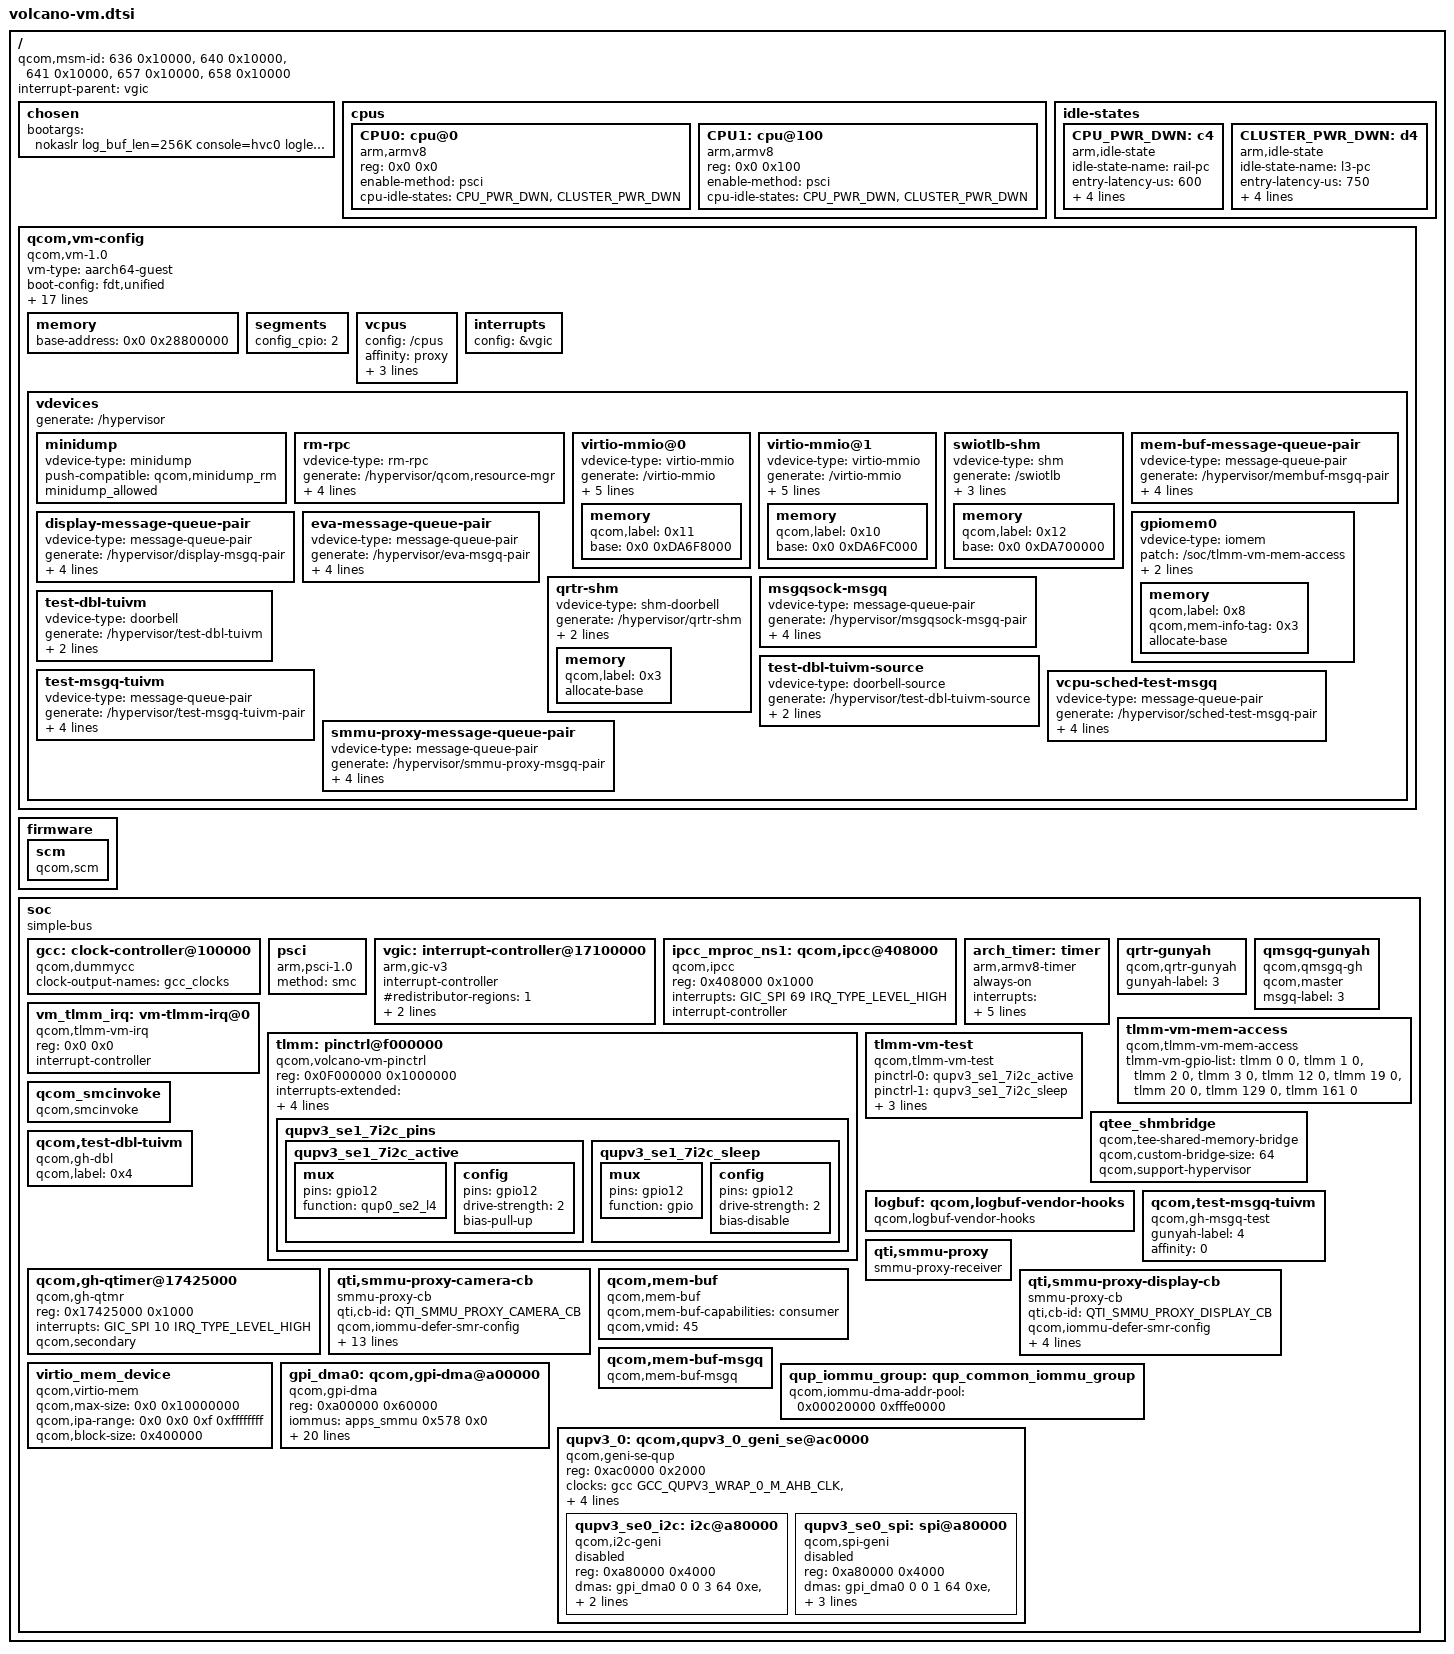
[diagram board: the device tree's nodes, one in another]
#include <dt-bindings/interrupt-controller/arm-gic.h>
#include <dt-bindings/clock/qcom,gcc-volcano.h>
#include <dt-bindings/arm/msm/qti-smmu-proxy-dt-ids.h>

/ {
	#address-cells = <0x2>;
	#size-cells = <0x2>;
	qcom,msm-id = <636 0x10000>, <640 0x10000>, <641 0x10000>, <657 0x10000>, <658 0x10000>;
	interrupt-parent = <&vgic>;

	chosen {
		bootargs = "nokaslr log_buf_len=256K console=hvc0 loglevel=8 memhp_default_state=online_movable memory_hotplug.memmap_on_memory=1";
	};

	cpus {
		#address-cells = <0x2>;
		#size-cells = <0x0>;

		CPU0: cpu@0 {
			compatible = "arm,armv8";
			reg = <0x0 0x0>;
			device_type = "cpu";
			enable-method = "psci";
			cpu-idle-states = <&CPU_PWR_DWN
					   &CLUSTER_PWR_DWN>;
		};

		CPU1: cpu@100 {
			compatible = "arm,armv8";
			reg = <0x0 0x100>;
			device_type = "cpu";
			enable-method = "psci";
			cpu-idle-states = <&CPU_PWR_DWN
					   &CLUSTER_PWR_DWN>;

		};
	};

	idle-states {
		CPU_PWR_DWN: c4 {  /* Using Gold C4 latencies */
			compatible = "arm,idle-state";
			idle-state-name = "rail-pc";
			entry-latency-us = <600>;
			exit-latency-us = <1300>;
			min-residency-us = <8136>;
			arm,psci-suspend-param = <0x40000004>;
			local-timer-stop;
		};

		CLUSTER_PWR_DWN: d4 { /* C4+D4 */
			compatible = "arm,idle-state";
			idle-state-name = "l3-pc";
			entry-latency-us = <750>;
			exit-latency-us = <2350>;
			min-residency-us = <9144>;
			arm,psci-suspend-param = <0x40000044>;
			local-timer-stop;
		};
	};

	qcom,vm-config {
		compatible = "qcom,vm-1.0";
		vm-type = "aarch64-guest";
		boot-config = "fdt,unified";
		os-type = "linux";
		kernel-entry-segment = "kernel";
		kernel-entry-offset = <0x0 0x0>;
		vendor = "QTI";
		image-name = "qcom,trustedvm";
		qcom,pasid = <0x0 0x1c>;
		qcom,qtee-config-info = "p=3,9,39,77,78,7C,8F,97,C8,FE,11B,159,199,47E,7F1,CDF,10C;";
		qcom,secdomain-ids = <45>;
		qcom,primary-vm-index = <0>;
		vm-uri = "vmuid/trusted-ui";
		vm-guid = "598085da-c516-5b25-a9c1-927a02819770";
		qcom,sensitive;

		iomemory-ranges = <0x0 0x408000 0x0 0x408000 0x0 0x1000 0x0
				   0x0 0xae8f000 0x0 0xae8f000 0x0 0x1000 0x0
				   0x0 0xa28000 0x0 0xa28000 0x0 0x4000 0x0>;
		/* For LEVM pored use cases is SE0(QUP0_SE0), for SE0 we used gpii6(QUPV3_0_GPII6)
		 * and irq no is 471.
		 */
		gic-irq-ranges = <101 101
				  471 471>; /* PVM->SVM IRQ transfer */

		vm-attrs = "crash-fatal", "context-dump";

		memory {
			#address-cells = <0x2>;
			#size-cells = <0x0>;
			/*
			 * IPA address linux image is loaded at. Must be within
			 * first 1GB due to memory hotplug requirement.
			 */
			base-address = <0x0 0x28800000 >;
		};

		segments {
			config_cpio = <2>;
		};

		vcpus {
			config = "/cpus";
			affinity = "proxy";
			affinity-map = <0 0>;
			sched-priority = <0>;       /* relative to PVM */
			sched-timeslice = <2000>;   /* in ms */
		};

		interrupts {
			config = &vgic;
		};

		vdevices {
			generate = "/hypervisor";

			minidump {
				vdevice-type = "minidump";
				push-compatible = "qcom,minidump_rm";
				minidump_allowed;
			};

			rm-rpc {
				vdevice-type = "rm-rpc";
				generate = "/hypervisor/qcom,resource-mgr";
				console-dev;
				message-size = <0x000000f0>;
				queue-depth = <0x00000008>;
				qcom,label = <0x1>;
			};

			virtio-mmio@0 {
				vdevice-type = "virtio-mmio";
				generate = "/virtio-mmio";
				peer-default;
				vqs-num = <0x1>;
				push-compatible = "virtio,mmio";
				dma-coherent;
				dma_base = <0x0 0x0>;
				memory {
					qcom,label = <0x11>;			//for persist.img
					#address-cells = <0x2>;
					base = <0x0 0xDA6F8000>;
				};
			};

			virtio-mmio@1 {
				vdevice-type = "virtio-mmio";
				generate = "/virtio-mmio";
				peer-default;
				vqs-num = <0x2>;
				push-compatible = "virtio,mmio";
				dma-coherent;
				dma_base = <0x0 0x4000>;
				memory {
					qcom,label = <0x10>;			//for system.img
					#address-cells = <0x2>;
					base = <0x0 0xDA6FC000>;
				};
			};

			swiotlb-shm {
				vdevice-type = "shm";
				generate = "/swiotlb";
				push-compatible = "swiotlb";
				peer-default;
				dma_base = <0x0 0x8000>;
				memory {
					qcom,label = <0x12>;
					#address-cells = <0x2>;
					base = <0x0 0xDA700000>;
				};
			};

			mem-buf-message-queue-pair {
				vdevice-type = "message-queue-pair";
				generate = "/hypervisor/membuf-msgq-pair";
				message-size = <0x000000f0>;
				queue-depth = <0x00000008>;
				peer-default;
				qcom,label = <0x0000001>;
			};

			display-message-queue-pair {
				vdevice-type = "message-queue-pair";
				generate = "/hypervisor/display-msgq-pair";
				message-size = <0x000000f0>;
				queue-depth = <0x00000008>;
				peer-default;
				qcom,label = <0x0000002>;
			};

			eva-message-queue-pair {
				vdevice-type = "message-queue-pair";
				generate = "/hypervisor/eva-msgq-pair";
				message-size = <0x000000f0>;
				queue-depth = <0x00000008>;
				peer-default;
				qcom,label =<0x7>;
			};

			gpiomem0 {
				vdevice-type = "iomem";
				patch = "/soc/tlmm-vm-mem-access";
				push-compatible = "qcom,tlmm-vm-mem-access";
				peer-default;
				memory {
					qcom,label = <0x8>;
					qcom,mem-info-tag = <0x3>;
					allocate-base;
				};
			};

			qrtr-shm {
				vdevice-type = "shm-doorbell";
				generate = "/hypervisor/qrtr-shm";
				push-compatible = "qcom,qrtr-gunyah-gen";
				peer-default;
				memory {
					qcom,label = <0x3>;
					allocate-base;
				};
			};

			msgqsock-msgq {
				vdevice-type = "message-queue-pair";
				generate = "/hypervisor/msgqsock-msgq-pair";
				message-size = <0xf0>;
				queue-depth = <0x8>;
				peer = "vm-name:qcom,oemvm";
				qcom,label = <0x3>;
			};

			test-dbl-tuivm {
				vdevice-type = "doorbell";
				generate = "/hypervisor/test-dbl-tuivm";
				qcom,label = <0x4>;
				peer-default;
			};

			test-dbl-tuivm-source {
				vdevice-type = "doorbell-source";
				generate = "/hypervisor/test-dbl-tuivm-source";
				qcom,label = <0x4>;
				peer-default;
			};

			test-msgq-tuivm {
				vdevice-type = "message-queue-pair";
				generate = "/hypervisor/test-msgq-tuivm-pair";
				message-size = <0xf0>;
				queue-depth = <0x8>;
				qcom,label = <0x4>;
				peer-default;
			};

			vcpu-sched-test-msgq {
				vdevice-type = "message-queue-pair";
				generate = "/hypervisor/sched-test-msgq-pair";
				message-size = <0xf0>;
				queue-depth = <0x8>;
				qcom,label = <0x8>;
				peer-default;
			};

			smmu-proxy-message-queue-pair {
				vdevice-type = "message-queue-pair";
				generate = "/hypervisor/smmu-proxy-msgq-pair";
				message-size = <0x000000f0>;
				queue-depth = <0x00000008>;
				peer-default;
				qcom,label = <0xA>;
			};
		};
	};

	firmware: firmware {
		scm {
			compatible = "qcom,scm";
		};
	};

	soc: soc { };
};

&soc {
	#address-cells = <1>;
	#size-cells = <1>;
	ranges = <0 0 0 0xffffffff>;
	compatible = "simple-bus";

	gcc: clock-controller@100000 {
		compatible = "qcom,dummycc";
		clock-output-names = "gcc_clocks";
		#clock-cells = <1>;
		#reset-cells = <1>;
	};

	psci {
		compatible = "arm,psci-1.0";
		method = "smc";
	};

	vgic: interrupt-controller@17100000 {
		compatible = "arm,gic-v3";
		interrupt-controller;
		#interrupt-cells = <0x3>;
		#redistributor-regions = <1>;
		redistributor-stride = <0x0 0x40000>;
		reg = <0x17100000 0x10000>,     /* GICD */
		      <0x17180000 0x100000>;    /* GICR * 8 */
	};

	ipcc_mproc_ns1: qcom,ipcc@408000 {
		compatible = "qcom,ipcc";
		reg = <0x408000 0x1000>;
		interrupts = <GIC_SPI 69 IRQ_TYPE_LEVEL_HIGH>;
		interrupt-controller;
		#interrupt-cells = <3>;
		#mbox-cells = <2>;
	};

	arch_timer: timer {
		compatible = "arm,armv8-timer";
		always-on;
		interrupts = <GIC_PPI 13 (GIC_CPU_MASK_SIMPLE(8) | IRQ_TYPE_LEVEL_LOW)>,
			     <GIC_PPI 14 (GIC_CPU_MASK_SIMPLE(8) | IRQ_TYPE_LEVEL_LOW)>,
			     <GIC_PPI 11 (GIC_CPU_MASK_SIMPLE(8) | IRQ_TYPE_LEVEL_LOW)>,
			     <GIC_PPI 12 (GIC_CPU_MASK_SIMPLE(8) | IRQ_TYPE_LEVEL_LOW)>;
		clock-frequency = <19200000>;
	};

	qrtr-gunyah {
		compatible = "qcom,qrtr-gunyah";
		gunyah-label = <3>;
	};

	qmsgq-gunyah {
		compatible = "qcom,qmsgq-gh";
		qcom,master;
		msgq-label = <3>;
	};

	vm_tlmm_irq: vm-tlmm-irq@0 {
		compatible = "qcom,tlmm-vm-irq";
		reg = <0x0 0x0>;
		interrupt-controller;
		#interrupt-cells = <2>;
	};

	tlmm: pinctrl@f000000 {
		compatible = "qcom,volcano-vm-pinctrl";
		reg = <0x0F000000 0x1000000>;
		interrupts-extended = <&vm_tlmm_irq 1 IRQ_TYPE_LEVEL_HIGH>;
		gpio-controller;
		#gpio-cells = <2>;
		interrupt-controller;
		#interrupt-cells = <2>;
		/* Valid pins */
		gpios = /bits/ 16 <0 1 2 3 12 19 20 129 161>;
	};

	tlmm-vm-mem-access {
		compatible = "qcom,tlmm-vm-mem-access";
		tlmm-vm-gpio-list = <&tlmm 0 0  &tlmm 1 0  &tlmm 2 0  &tlmm 3 0
				     &tlmm 12 0 &tlmm 19 0 &tlmm 20 0 &tlmm 129 0
				     &tlmm 161 0>;
	};

	tlmm-vm-test {
		compatible = "qcom,tlmm-vm-test";
		pinctrl-names = "active", "sleep";
		pinctrl-0 = <&qupv3_se1_7i2c_active>;
		pinctrl-1 = <&qupv3_se1_7i2c_sleep>;
		tlmm-vm-gpio-list = <&tlmm 0 0  &tlmm 1 0  &tlmm 2 0  &tlmm 3 0
				     &tlmm 12 0 &tlmm 19 0 &tlmm 20 0 &tlmm 129 0
				     &tlmm 161 0>;
	};

	pinctrl@f000000 {
		qupv3_se1_7i2c_pins: qupv3_se1_7i2c_pins {
			qupv3_se1_7i2c_active: qupv3_se1_7i2c_active {
				mux {
					pins = "gpio12";
					function = "qup0_se2_l4";
				};

				config {
					pins = "gpio12";
					drive-strength = <2>;
					bias-pull-up;
				};
			};

			qupv3_se1_7i2c_sleep: qupv3_se1_7i2c_sleep {
				mux {
					pins = "gpio12";
					function = "gpio";
				};

				config {
					pins = "gpio12";
					drive-strength = <2>;
					bias-disable;
				};
			};
		};
	};

	qcom_smcinvoke {
		compatible = "qcom,smcinvoke";
	};

	qtee_shmbridge {
		compatible = "qcom,tee-shared-memory-bridge";
		qcom,custom-bridge-size = <64>;
		qcom,support-hypervisor;
	};

	logbuf: qcom,logbuf-vendor-hooks {
		compatible = "qcom,logbuf-vendor-hooks";
	};

	qcom,test-dbl-tuivm {
		compatible = "qcom,gh-dbl";
		qcom,label = <0x4>;
	};

	qcom,test-msgq-tuivm {
		compatible = "qcom,gh-msgq-test";
		gunyah-label = <4>;
		affinity = <0>;
	};

	qcom,gh-qtimer@17425000 {
		compatible = "qcom,gh-qtmr";
		reg = <0x17425000 0x1000>;
		reg-names = "qtmr-base";
		interrupts = <GIC_SPI 10 IRQ_TYPE_LEVEL_HIGH>;
		interrupt-names = "qcom,qtmr-intr";
		qcom,secondary;
	};

	qti,smmu-proxy {
		compatible = "smmu-proxy-receiver";
	};

	qti,smmu-proxy-camera-cb {
		compatible = "smmu-proxy-cb";
		qti,cb-id = <QTI_SMMU_PROXY_CAMERA_CB>;
		qcom,iommu-defer-smr-config;
		qcom,iommu-dma-addr-pool = <0x00000000 0xffffffff>;
		iommus = <&apps_smmu 0x18c2 0x00>,
			<&apps_smmu 0x1801 0x60>,
			<&apps_smmu 0x1821 0x60>,
			<&apps_smmu 0x1841 0x60>,
			<&apps_smmu 0x1861 0x60>,
			<&apps_smmu 0x18E1 0x00>,
			<&apps_smmu 0x1901 0x20>,
			<&apps_smmu 0x1921 0x20>,
			<&apps_smmu 0x1941 0x00>,
			<&apps_smmu 0x08A1 0x20>,
			<&apps_smmu 0x0881 0x20>;
		dma-coherent;
	};

	qti,smmu-proxy-display-cb {
		compatible = "smmu-proxy-cb";
		qti,cb-id = <QTI_SMMU_PROXY_DISPLAY_CB>;
		qcom,iommu-defer-smr-config;
		qcom,iommu-dma-addr-pool = <0x00020000 0xfffe0000>;
		iommus = <&apps_smmu 0x1c01 0x0>;
		dma-coherent;
	};

	qcom,mem-buf {
		compatible = "qcom,mem-buf";
		qcom,mem-buf-capabilities = "consumer";
		qcom,vmid = <45>;
	};

	qcom,mem-buf-msgq {
		compatible = "qcom,mem-buf-msgq";
	};

	virtio_mem_device {
		compatible = "qcom,virtio-mem";
		/* Must be memory_block_size_bytes() aligned */
		qcom,max-size = <0x0 0x10000000>;
		qcom,ipa-range = <0x0 0x0 0xf 0xffffffff>;
		qcom,block-size = <0x400000>;
	};

	qup_iommu_group: qup_common_iommu_group {
			qcom,iommu-dma-addr-pool = <0x00020000 0xfffe0000>;
	};

	/* GPI Instance */
	gpi_dma0: qcom,gpi-dma@a00000 {
		compatible = "qcom,gpi-dma";
		#dma-cells = <5>;
		reg = <0xa00000 0x60000>;
		reg-names = "gpi-top";
		iommus = <&apps_smmu 0x578 0x0>;
		qcom,iommu-group = <&qup_iommu_group>;
		dma-coherent;
		qcom,max-num-gpii = <12>;
		interrupts = <GIC_SPI 433 IRQ_TYPE_LEVEL_HIGH>,
			<GIC_SPI 434 IRQ_TYPE_LEVEL_HIGH>,
			<GIC_SPI 435 IRQ_TYPE_LEVEL_HIGH>,
			<GIC_SPI 436 IRQ_TYPE_LEVEL_HIGH>,
			<GIC_SPI 437 IRQ_TYPE_LEVEL_HIGH>,
			<GIC_SPI 438 IRQ_TYPE_LEVEL_HIGH>,
			<GIC_SPI 439 IRQ_TYPE_LEVEL_HIGH>,
			<GIC_SPI 595 IRQ_TYPE_LEVEL_HIGH>,
			<GIC_SPI 596 IRQ_TYPE_LEVEL_HIGH>,
			<GIC_SPI 597 IRQ_TYPE_LEVEL_HIGH>,
			<GIC_SPI 598 IRQ_TYPE_LEVEL_HIGH>,
			<GIC_SPI 599 IRQ_TYPE_LEVEL_HIGH>;
		qcom,static-gpii-mask = <0x40>;
		qcom,gpii-mask = <0x0>;
		qcom,ev-factor = <1>;
		qcom,gpi-ee-offset = <0x10000>;
		qcom,le-vm;
		status = "ok";
	};

	/* QUPv3_0 wrapper instance */
	qupv3_0: qcom,qupv3_0_geni_se@ac0000 {
		compatible = "qcom,geni-se-qup";
		reg = <0xac0000 0x2000>;
		#address-cells = <1>;
		#size-cells = <1>;
		clock-names = "m-ahb", "s-ahb";
		clocks = <&gcc GCC_QUPV3_WRAP_0_M_AHB_CLK>,
			<&gcc GCC_QUPV3_WRAP_0_S_AHB_CLK>;
		iommus = <&apps_smmu 0x578 0x0>;
		qcom,iommu-group = <&qup_iommu_group>;
		dma-coherent;
		ranges;
		status = "ok";

		qupv3_se0_i2c: i2c@a80000 {
			compatible = "qcom,i2c-geni";
			reg = <0xa80000 0x4000>;
			#address-cells = <1>;
			#size-cells = <0>;
			dmas = <&gpi_dma0 0 0 3 64 0xe>,
				<&gpi_dma0 1 0 3 64 0xe>;
			dma-names = "tx", "rx";
			qcom,le-vm;
			status = "disabled";
		};

		qupv3_se0_spi: spi@a80000 {
			compatible = "qcom,spi-geni";
			reg = <0xa80000 0x4000>;
			#address-cells = <1>;
			#size-cells = <0>;
			reg-names = "se_phys";
			dmas = <&gpi_dma0 0 0 1 64 0xe>,
				<&gpi_dma0 1 0 1 64 0xe>;
			dma-names = "tx", "rx";
			spi-max-frequency = <50000000>;
			qcom,le-vm;
			status = "disabled";
		};
	};
};

#include "volcano-vm-dma-heaps.dtsi"
#include "msm-arm-smmu-volcano-vm.dtsi"
